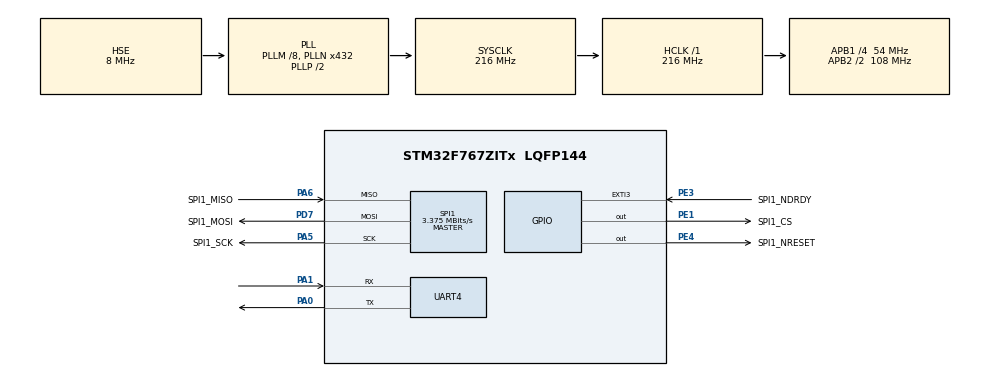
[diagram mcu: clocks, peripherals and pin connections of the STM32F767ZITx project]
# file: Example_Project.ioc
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Dma.Request0=SPI1_RX
Dma.Request1=SPI1_TX
Dma.SPI1_RX.0.Direction=DMA_PERIPH_TO_MEMORY
Dma.SPI1_RX.0.FIFOMode=DMA_FIFOMODE_DISABLE
Dma.SPI1_RX.0.Instance=DMA2_Stream0
Dma.SPI1_RX.0.MemDataAlignment=DMA_MDATAALIGN_BYTE
Dma.SPI1_RX.0.MemInc=DMA_MINC_ENABLE
Dma.SPI1_RX.0.Mode=DMA_NORMAL
Dma.SPI1_RX.0.PeriphDataAlignment=DMA_PDATAALIGN_BYTE
Dma.SPI1_RX.0.PeriphInc=DMA_PINC_DISABLE
Dma.SPI1_RX.0.Priority=DMA_PRIORITY_LOW
Dma.SPI1_TX.1.Direction=DMA_MEMORY_TO_PERIPH
Dma.SPI1_TX.1.FIFOMode=DMA_FIFOMODE_DISABLE
Dma.SPI1_TX.1.Instance=DMA2_Stream3
Dma.SPI1_TX.1.MemDataAlignment=DMA_MDATAALIGN_BYTE
Dma.SPI1_TX.1.MemInc=DMA_MINC_ENABLE
Dma.SPI1_TX.1.Mode=DMA_NORMAL
Dma.SPI1_TX.1.PeriphDataAlignment=DMA_PDATAALIGN_BYTE
Dma.SPI1_TX.1.PeriphInc=DMA_PINC_DISABLE
Dma.SPI1_TX.1.Priority=DMA_PRIORITY_LOW
FREERTOS.Tasks01=defaultTask,24,512,StartDefaultTask,Default,NULL,Dynamic,NULL,NULL
FREERTOS.configENABLE_FPU=1
FREERTOS.configMINIMAL_STACK_SIZE=512
Mcu.Family=STM32F7
Mcu.Name=STM32F767ZITx
Mcu.Package=LQFP144
NVIC.DMA2_Stream0_IRQn=true\:5\:0\:false\:false\:true\:true\:false\:true
NVIC.DMA2_Stream3_IRQn=true\:5\:0\:false\:false\:true\:true\:false\:true
NVIC.EXTI3_IRQn=true\:5\:0\:false\:false\:true\:true\:true\:true
NVIC.PriorityGroup=NVIC_PRIORITYGROUP_4
NVIC.TIM2_IRQn=true\:0\:0\:false\:false\:true\:false\:false\:true
NVIC.TimeBase=TIM2_IRQn
NVIC.TimeBaseIP=TIM2
NVIC.UART4_IRQn=true\:5\:0\:false\:false\:true\:true\:true\:true
PA0/WKUP.Mode=Asynchronous
PA0/WKUP.Signal=UART4_TX
PA1.Mode=Asynchronous
PA1.Signal=UART4_RX
PA5.GPIO_Label=SPI1_SCK
PA5.Mode=Full_Duplex_Master
PA5.Signal=SPI1_SCK
PA6.GPIO_Label=SPI1_MISO
PA6.Mode=Full_Duplex_Master
PA6.Signal=SPI1_MISO
PC14/OSC32_IN.Mode=LSE-External-Oscillator
PC14/OSC32_IN.Signal=RCC_OSC32_IN
PC15/OSC32_OUT.Mode=LSE-External-Oscillator
PC15/OSC32_OUT.Signal=RCC_OSC32_OUT
PD7.GPIO_Label=SPI1_MOSI
PD7.Mode=Full_Duplex_Master
PD7.Signal=SPI1_MOSI
PE1.GPIO_Label=SPI1_CS
PE1.Signal=GPIO_Output
PE3.GPIO_Label=SPI1_NDRDY
PE3.GPIO_ModeDefaultEXTI=GPIO_MODE_IT_FALLING
PE3.Signal=GPXTI3
PE4.GPIO_Label=SPI1_NRESET
PE4.GPIO_PuPd=GPIO_PULLUP
PE4.PinState=GPIO_PIN_SET
PE4.Signal=GPIO_Output
PH0/OSC_IN.Mode=HSE-External-Clock-Source
PH0/OSC_IN.Signal=RCC_OSC_IN
PH1/OSC_OUT.Mode=HSE-External-Clock-Source
PH1/OSC_OUT.Signal=RCC_OSC_OUT
ProjectManager.HeapSize=0x200
ProjectManager.StackSize=0x400
ProjectManager.TargetToolchain=Makefile
RCC.AHBFreq_Value=216000000
RCC.APB1CLKDivider=RCC_HCLK_DIV4
RCC.APB1Freq_Value=54000000
RCC.APB1TimFreq_Value=108000000
RCC.APB2CLKDivider=RCC_HCLK_DIV2
RCC.APB2Freq_Value=108000000
RCC.APB2TimCLKDivider=2
RCC.APB2TimFreq_Value=216000000
RCC.CortexFreq_Value=216000000
RCC.HCLKFreq_Value=216000000
RCC.HSE_VALUE=8000000
RCC.HSI_VALUE=16000000
RCC.PLLM=8
RCC.PLLN=432
RCC.PLLSourceVirtual=RCC_PLLSOURCE_HSE
RCC.SYSCLKFreq_VALUE=216000000
RCC.SYSCLKSource=RCC_SYSCLKSOURCE_PLLCLK
RCC.USBFreq_Value=216000000
RCC.VCOOutputFreq_Value=432000000
SPI1.BaudRatePrescaler=SPI_BAUDRATEPRESCALER_32
SPI1.CLKPhase=SPI_PHASE_2EDGE
SPI1.CLKPolarity=SPI_POLARITY_LOW
SPI1.CalculateBaudRate=3.375 MBits/s
SPI1.DataSize=SPI_DATASIZE_8BIT
SPI1.Direction=SPI_DIRECTION_2LINES
SPI1.Mode=SPI_MODE_MASTER
SPI1.VirtualType=VM_MASTER
VP_FREERTOS_VS_CMSIS_V2.Mode=CMSIS_V2
VP_SYS_VS_tim2.Mode=TIM2
board=custom

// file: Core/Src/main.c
/* USER CODE BEGIN Header */
/**
  ******************************************************************************
  * @file           : main.c
  * @brief          : Main program body
  ******************************************************************************
  * @attention
  *
  * <h2><center>&copy; Copyright (c) 2021 STMicroelectronics.
  * All rights reserved.</center></h2>
  *
  * This software component is licensed by ST under Ultimate Liberty license
  * SLA0044, the "License"; You may not use this file except in compliance with
  * the License. You may obtain a copy of the License at:
  *                             www.st.com/SLA0044
  *
  ******************************************************************************
  */
/* USER CODE END Header */
#include "main.h"
#include "cmsis_os.h"

/* USER CODE BEGIN Includes */
#include "ADS131A04.h"
#include "stdio.h"
/* USER CODE END Includes */

SPI_HandleTypeDef hspi1;
DMA_HandleTypeDef hdma_spi1_rx;
DMA_HandleTypeDef hdma_spi1_tx;

UART_HandleTypeDef huart4;

/* Definitions for defaultTask */
osThreadId_t defaultTaskHandle;
const osThreadAttr_t defaultTask_attributes = {
  .name = "defaultTask",
  .priority = (osPriority_t) osPriorityNormal,
  .stack_size = 512 * 4
};

void SystemClock_Config(void);
static void MX_GPIO_Init(void);
static void MX_DMA_Init(void);
static void MX_SPI1_Init(void);
static void MX_UART4_Init(void);
void StartDefaultTask(void *argument);

int main(void)
{

  /* MCU Configuration--------------------------------------------------------*/

  /* Reset of all peripherals, Initializes the Flash interface and the Systick. */
  HAL_Init();

  /* Configure the system clock */
  SystemClock_Config();

  /* Initialize all configured peripherals */
  MX_GPIO_Init();
  MX_DMA_Init();
  MX_SPI1_Init();
  MX_UART4_Init();
  /* USER CODE BEGIN 2 */
  ADS131A04_init(ADS131A04_ADC1, &hspi1);
  /* USER CODE END 2 */

  /* Init scheduler */
  osKernelInitialize();

  /* Create the thread(s) */
  /* creation of defaultTask */
  defaultTaskHandle = osThreadNew(StartDefaultTask, NULL, &defaultTask_attributes);

  /* Start scheduler */
  osKernelStart();

  /* We should never get here as control is now taken by the scheduler */
  /* Infinite loop */
  while (1)
  {

  }
}

void SystemClock_Config(void)
{
  RCC_OscInitTypeDef RCC_OscInitStruct = {0};
  RCC_ClkInitTypeDef RCC_ClkInitStruct = {0};
  RCC_PeriphCLKInitTypeDef PeriphClkInitStruct = {0};

  /** Configure LSE Drive Capability
  */
  HAL_PWR_EnableBkUpAccess();
  /** Configure the main internal regulator output voltage
  */
  __HAL_RCC_PWR_CLK_ENABLE();
  __HAL_PWR_VOLTAGESCALING_CONFIG(PWR_REGULATOR_VOLTAGE_SCALE1);
  /** Initializes the RCC Oscillators according to the specified parameters
  * in the RCC_OscInitTypeDef structure.
  */
  RCC_OscInitStruct.OscillatorType = RCC_OSCILLATORTYPE_HSE;
  RCC_OscInitStruct.HSEState = RCC_HSE_BYPASS;
  RCC_OscInitStruct.PLL.PLLState = RCC_PLL_ON;
  RCC_OscInitStruct.PLL.PLLSource = RCC_PLLSOURCE_HSE;
  RCC_OscInitStruct.PLL.PLLM = 8;
  RCC_OscInitStruct.PLL.PLLN = 432;
  RCC_OscInitStruct.PLL.PLLP = RCC_PLLP_DIV2;
  RCC_OscInitStruct.PLL.PLLQ = 2;
  if (HAL_RCC_OscConfig(&RCC_OscInitStruct) != HAL_OK)
  {
    Error_Handler();
  }
  /** Activate the Over-Drive mode
  */
  if (HAL_PWREx_EnableOverDrive() != HAL_OK)
  {
    Error_Handler();
  }
  /** Initializes the CPU, AHB and APB buses clocks
  */
  RCC_ClkInitStruct.ClockType = RCC_CLOCKTYPE_HCLK|RCC_CLOCKTYPE_SYSCLK
                              |RCC_CLOCKTYPE_PCLK1|RCC_CLOCKTYPE_PCLK2;
  RCC_ClkInitStruct.SYSCLKSource = RCC_SYSCLKSOURCE_PLLCLK;
  RCC_ClkInitStruct.AHBCLKDivider = RCC_SYSCLK_DIV1;
  RCC_ClkInitStruct.APB1CLKDivider = RCC_HCLK_DIV4;
  RCC_ClkInitStruct.APB2CLKDivider = RCC_HCLK_DIV2;

  if (HAL_RCC_ClockConfig(&RCC_ClkInitStruct, FLASH_LATENCY_7) != HAL_OK)
  {
    Error_Handler();
  }
  PeriphClkInitStruct.PeriphClockSelection = RCC_PERIPHCLK_UART4;
  PeriphClkInitStruct.Uart4ClockSelection = RCC_UART4CLKSOURCE_PCLK1;
  if (HAL_RCCEx_PeriphCLKConfig(&PeriphClkInitStruct) != HAL_OK)
  {
    Error_Handler();
  }
}

static void MX_SPI1_Init(void)
{

  /* SPI1 parameter configuration*/
  hspi1.Instance = SPI1;
  hspi1.Init.Mode = SPI_MODE_MASTER;
  hspi1.Init.Direction = SPI_DIRECTION_2LINES;
  hspi1.Init.DataSize = SPI_DATASIZE_8BIT;
  hspi1.Init.CLKPolarity = SPI_POLARITY_LOW;
  hspi1.Init.CLKPhase = SPI_PHASE_2EDGE;
  hspi1.Init.NSS = SPI_NSS_SOFT;
  hspi1.Init.BaudRatePrescaler = SPI_BAUDRATEPRESCALER_32;
  hspi1.Init.FirstBit = SPI_FIRSTBIT_MSB;
  hspi1.Init.TIMode = SPI_TIMODE_DISABLE;
  hspi1.Init.CRCCalculation = SPI_CRCCALCULATION_DISABLE;
  hspi1.Init.CRCPolynomial = 7;
  hspi1.Init.CRCLength = SPI_CRC_LENGTH_DATASIZE;
  hspi1.Init.NSSPMode = SPI_NSS_PULSE_DISABLE;
  if (HAL_SPI_Init(&hspi1) != HAL_OK)
  {
    Error_Handler();
  }

}

static void MX_UART4_Init(void)
{

  huart4.Instance = UART4;
  huart4.Init.BaudRate = 115200;
  huart4.Init.WordLength = UART_WORDLENGTH_8B;
  huart4.Init.StopBits = UART_STOPBITS_1;
  huart4.Init.Parity = UART_PARITY_NONE;
  huart4.Init.Mode = UART_MODE_TX_RX;
  huart4.Init.HwFlowCtl = UART_HWCONTROL_NONE;
  huart4.Init.OverSampling = UART_OVERSAMPLING_16;
  huart4.Init.OneBitSampling = UART_ONE_BIT_SAMPLE_DISABLE;
  huart4.AdvancedInit.AdvFeatureInit = UART_ADVFEATURE_NO_INIT;
  if (HAL_UART_Init(&huart4) != HAL_OK)
  {
    Error_Handler();
  }

}

static void MX_DMA_Init(void)
{

  /* DMA controller clock enable */
  __HAL_RCC_DMA2_CLK_ENABLE();

  /* DMA interrupt init */
  /* DMA2_Stream0_IRQn interrupt configuration */
  HAL_NVIC_SetPriority(DMA2_Stream0_IRQn, 5, 0);
  HAL_NVIC_EnableIRQ(DMA2_Stream0_IRQn);
  /* DMA2_Stream3_IRQn interrupt configuration */
  HAL_NVIC_SetPriority(DMA2_Stream3_IRQn, 5, 0);
  HAL_NVIC_EnableIRQ(DMA2_Stream3_IRQn);

}

static void MX_GPIO_Init(void)
{
  GPIO_InitTypeDef GPIO_InitStruct = {0};

  /* GPIO Ports Clock Enable */
  __HAL_RCC_GPIOE_CLK_ENABLE();
  __HAL_RCC_GPIOC_CLK_ENABLE();
  __HAL_RCC_GPIOH_CLK_ENABLE();
  __HAL_RCC_GPIOA_CLK_ENABLE();
  __HAL_RCC_GPIOD_CLK_ENABLE();

  /*Configure GPIO pin Output Level */
  HAL_GPIO_WritePin(SPI1_NRESET_GPIO_Port, SPI1_NRESET_Pin, GPIO_PIN_SET);

  /*Configure GPIO pin Output Level */
  HAL_GPIO_WritePin(SPI1_CS_GPIO_Port, SPI1_CS_Pin, GPIO_PIN_RESET);

  /*Configure GPIO pin : SPI1_NDRDY_Pin */
  GPIO_InitStruct.Pin = SPI1_NDRDY_Pin;
  GPIO_InitStruct.Mode = GPIO_MODE_IT_FALLING;
  GPIO_InitStruct.Pull = GPIO_NOPULL;
  HAL_GPIO_Init(SPI1_NDRDY_GPIO_Port, &GPIO_InitStruct);

  /*Configure GPIO pin : SPI1_NRESET_Pin */
  GPIO_InitStruct.Pin = SPI1_NRESET_Pin;
  GPIO_InitStruct.Mode = GPIO_MODE_OUTPUT_PP;
  GPIO_InitStruct.Pull = GPIO_PULLUP;
  GPIO_InitStruct.Speed = GPIO_SPEED_FREQ_LOW;
  HAL_GPIO_Init(SPI1_NRESET_GPIO_Port, &GPIO_InitStruct);

  /*Configure GPIO pin : SPI1_CS_Pin */
  GPIO_InitStruct.Pin = SPI1_CS_Pin;
  GPIO_InitStruct.Mode = GPIO_MODE_OUTPUT_PP;
  GPIO_InitStruct.Pull = GPIO_NOPULL;
  GPIO_InitStruct.Speed = GPIO_SPEED_FREQ_LOW;
  HAL_GPIO_Init(SPI1_CS_GPIO_Port, &GPIO_InitStruct);

  /* EXTI interrupt init*/
  HAL_NVIC_SetPriority(EXTI3_IRQn, 5, 0);
  HAL_NVIC_EnableIRQ(EXTI3_IRQn);

}

void StartDefaultTask(void *argument)
{
  /* USER CODE BEGIN 5 */
  char str[1000];
  memset(str, 0, strlen(str));
  /* Infinite loop */
  for(;;)
  {
    sprintf(str, "ADC1 Information\r\nCH1: %f\r\nCH2: %f\r\nCH3: %f\r\nCH4: %f\r\n\r\n", adcConfA->chData[0].v, adcConfA->chData[1].v, adcConfA->chData[2].v, adcConfA->chData[3].v);
    HAL_UART_Transmit(&huart4, (uint8_t*)str, strlen(str), 500);
    osDelay(1000);
  }
  /* USER CODE END 5 */
}

 /**
  * @brief  Period elapsed callback in non blocking mode
  * @note   This function is called  when TIM2 interrupt took place, inside
  * HAL_TIM_IRQHandler(). It makes a direct call to HAL_IncTick() to increment
  * a global variable "uwTick" used as application time base.
  * @param  htim : TIM handle
  * @retval None
  */
void HAL_TIM_PeriodElapsedCallback(TIM_HandleTypeDef *htim)
{
  if (htim->Instance == TIM2) {
    HAL_IncTick();
  }
}

void Error_Handler(void)
{
  __disable_irq();
  while (1)
  {
  }
}

/************************ (C) COPYRIGHT STMicroelectronics *****END OF FILE****/
